# M4KL register map
File version: 0.1
Registers are 32-bit, read-write, reset 0x0 unless marked. A register's access mark holds for its fields unless they carry their own. Offsets are from the block's base; [hi:lo] are bit positions; {n}, {i} and the like mark numbered series.

## VE — Advanced Vector Engine Plus (A-VE+)
Base 0x400EB000
0x00 EN — VE enable_disable
  [0] VEEN
0x04 CPURUNTRG wo — CPU start trigger selection
  [0] VCPURT
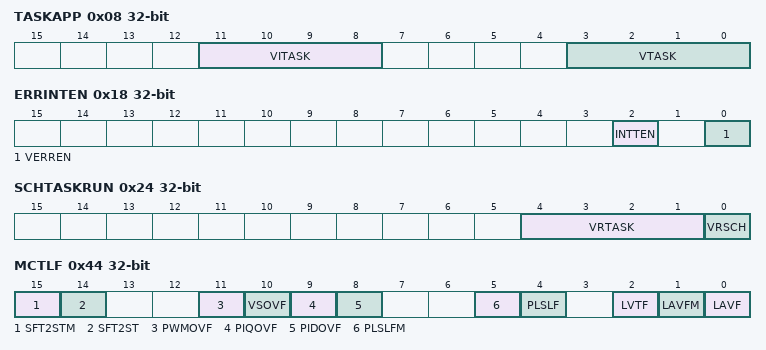
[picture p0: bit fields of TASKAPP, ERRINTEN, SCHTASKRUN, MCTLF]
0x08 TASKAPP — Task selection
  [11:8] VITASK, [3:0] VTASK
0x0C ACTSCH — Operation schedule selection
  [3:0] VACT
0x10 REPTIME — Schedule repeat count
  [3:0] VREP
0x14 TRGMODE — Start trigger mode
  [1:0] VTRG
0x18 ERRINTEN — Error interrupt enable_disable
  [2] INTTEN, [0] VERREN
0x1C COMPEND wo — VE forced termination
  [0] VCEND
0x20 ERRDET ro — Error detection
  [0] VERRD
0x24 SCHTASKRUN ro — Schedule executing flag_executing task
  [4:1] VRTASK, [0] VRSCH
{0x2C+4i} TMPREG{i} (i=0..5) — Temporary register
0x44 MCTLF — Status flags
  [15] SFT2STM, [14] SFT2ST, [11] PWMOVF, [10] VSOVF, [9] PIQOVF, [8] PIDOVF, [5] PLSLFM, [4] PLSLF, [2] LVTF, [1] LAVFM, [0] LAVF
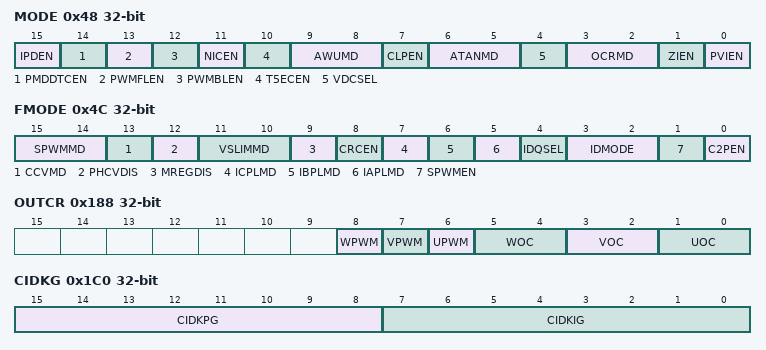
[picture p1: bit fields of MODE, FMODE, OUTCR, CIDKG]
0x48 MODE — Task control mode
  [15] IPDEN, [14] PMDDTCEN, [13] PWMFLEN, [12] PWMBLEN, [11] NICEN, [10] T5ECEN, [9:8] AWUMD, [7] CLPEN, [6:5] ATANMD, [4] VDCSEL, [3:2] OCRMD, [1] ZIEN, [0] PVIEN
0x4C FMODE — Flow control
  [15:14] SPWMMD, [13] CCVMD, [12] PHCVDIS, [11:10] VSLIMMD, [9] MREGDIS, [8] CRCEN, [7] ICPLMD, [6] IBPLMD, [5] IAPLMD, [4] IDQSEL, [3:2] IDMODE, [1] SPWMEN, [0] C2PEN
0x50 TPWM — PWM period rate (PWM period _s_ * maximum speed * 2^16) setting
  [15:0] TPWM
0x54 OMEGA — Rotation speed (speed _Hz_ _ maximum speed * 2^15) setting
  [15:0] OMEGA
0x58 THETA — Motor phase (motor phase _deg_ _ 360 * 2^16) setting
  [15:0] THETA
0x5C IDREF — d-axis reference value (current _A_ _ maximum current * 2^15)
  [15:0] IDREF
0x60 IQREF — q-axis reference value (current _A_ _ maximum current * 2^15)
  [15:0] IQREF
0x64 VD — d-axis voltage (voltage _V_ _ maximum voltage * 2^31)
0x68 VQ — q-axis voltage (voltage _V_ _ maximum voltage * 2^31)
0x6C CIDKI — Integral coefficient for PI control of d-axis
  [15:0] CIDKI
0x70 CIDKP — Proportional coefficient for PI control of d-axis
  [15:0] CIDKP
0x74 CIQKI — Integral coefficient for PI control of q-axis
  [15:0] CIQKI
0x78 CIQKP — Proportional coefficient for PI control of q-axis
  [15:0] CIQKP
0x7C VDIH — Upper 32 bits of integral term (VDI ) of d-axis voltage
0x80 VDILH — Lower 32 bits of integral term (VDI) of d-axis voltage
  [31:16] VDILH
0x84 VQIH — Upper 32 bits of integral term (VQI) of q-axis voltage
0x88 VQILH — Lower 32 bits of integral term (VQI) of q-axis voltage
  [31:16] VQILH
0x8C FPWMCHG — Switching speed (for 2-phase modulation and shift PWM)
  [15:0] FPWMCHG
0x90 PWMOFS — SHIFT2 PWM Offset register
  [15:0] PWMOFS
0x94 MINPLS — Minimum pulse width
  [15:0] MINPLS
0x98 TRGCRC — Synchronizing trigger correction value
  [15:0] TRGCRC
0x9C VDCL — Cosine value at THETA for output conversion (Q15 data)
  [15:0] VDCL
0xA0 COS — Cosine value at THETA for output conversion (Q15 data)
  [15:0] COS
0xA4 SIN — Sine value at THETA for output conversion (Q15 data)
  [15:0] SIN
0xA8 COSM — Previous cosine value for input processing (Q15 data)
  [15:0] COSM
0xAC SINM — Previous sine value for input processing (Q15 data)
  [15:0] SINM
0xB0 SECTOR — Sector information (0-11)
  [3:0] SECTOR
0xB4 SECTORM — Previous sector information for input processing (0-11)
  [3:0] SECTORM
0xB8 IAO — AD conversion result of a-phase zero-current
  [15:0] IAO
0xBC IBO — AD conversion result of b-phase zero-current
  [15:0] IBO
0xC0 ICO — AD conversion result of c-phase zero-current
  [15:0] ICO
0xC4 IAADC — AD conversion result of a-phase current
  [15:0] IAADC
0xC8 IBADC — AD conversion result of b-phase current
  [15:0] IBADC
0xCC ICADC — AD conversion result of c-phase current
  [15:0] ICADC
0xD0 VDC — DC supply voltage (voltage _V_ _ maximum voltage * 2^15)
  [15:0] VDC
0xD4 ID — d-axis current (current _A_ _ maximum current * 2^31)
0xD8 IQ — q-axis current (current _A_ _ maximum current * 2^31)
0x178 TADC — ADC start wait setting
  [15:0] TADC
0x17C CMPU — PMD control_ CMPU setting
  [15:0] VCMPU
0x180 CMPV — PMD control_ CMPV setting
  [15:0] VCMPV
0x184 CMPW — PMD control_ CMPW setting
  [15:0] VCMPW
0x188 OUTCR — PMD control_ Output control (MDOUT)
  [8] WPWM, [7] VPWM, [6] UPWM, [5:4] WOC, [3:2] VOC, [1:0] UOC
0x18C TRGCMP0 — PMD control_ TRGCMP0 setting
  [15:0] VTRGCMP0
0x190 TRGCMP1 — PMD control_ TRGCMP1 setting
  [15:0] VTRGCMP1
0x194 TRGSEL — PMD control_ Trigger selection
  [2:0] VTRGSEL
0x198 EMGRS wo — PMD control_ EMG return (EMGCR_EMGRS_)
  [0] EMGRS
0x1BC PIOLIM — PI controled output limit value setting
  [15:0] PIOLIM
0x1C0 CIDKG — PI controled d-axis coefficient range setting
  [15:8] CIDKPG, [7:0] CIDKIG
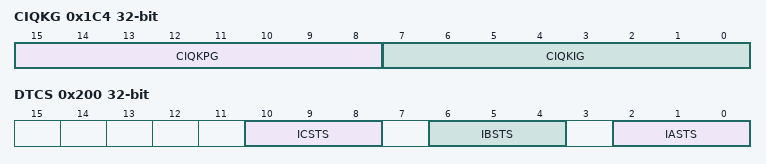
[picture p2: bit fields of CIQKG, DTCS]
0x1C4 CIQKG — PI controled q-axis coefficient range setting
  [15:8] CIQKPG, [7:0] CIQKIG
0x1C8 VSLIM — Voltage scalar limits
  [15:0] VSLIM
0x1CC VDQ — Voltage scalar
  [15:0] VDQ
0x1D0 DELTA — Declination angle
  [15:0] DELTA
0x1D4 CPHI — Motor interlinkage magnetic flux
  [15:0] CPHI
0x1D8 CLD — Motor q-axis inductance
  [15:0] CLD
0x1DC CLQ — Motor d-axis inductance
  [15:0] CLQ
0x1E0 CR — Motor resistance value
  [15:0] CR
0x1E4 CPHIG — Motor magnetic flux range setting
  [2:0] CPHIG
0x1E8 CLG — Motor inductance range setting
  [2:0] CLG
0x1EC CRG — Motor resistance range setting
  [2:0] CRG
0x1F0 VDE — Non-interference controled d-axis voltage
  [15:0] VDE
0x1F4 VQE — Non-interference controled q-axis voltage
  [15:0] VQE
0x1F8 DTC — Dead time compensation
  [15:0] DTC
0x1FC HYS — Hysteresis width for current discrimination
  [15:0] HYS
0x200 DTCS — Dead time compensation control _ status
  [10:8] ICSTS, [6:4] IBSTS, [2:0] IASTS
0x204 PWMMAX — PWM upper limit setting
  [15:0] PWMMAX
0x208 PWMMIN — PWM lower limit setting
  [15:0] PWMMIN
0x20C THTCLP — Clipped phase value setting
  [15:0] THTCLP
0x210 HYS2 — The second threshold value for determining the current polarity
  [15:0] HYS2
0x214 VALPHA — ALPHA-phase voltage
0x218 VBETA — BETA-phase voltage
0x21C VDUTYA — A-phase duty
0x220 VDUTYB — B-phase duty
0x224 VDUTYC — C-phase duty
0x228 IALPHA — ALPHA-phase current
0x22C IBETA — BETA-phase current
0x230 IA — A-phase current
0x234 IB — B-phase current
0x238 IC — C-phase current
0x23C VDELTA — VDQ Declination angle
  [15:0] VDELTA
0x240 VDCRC — d-axis voltage correction value
  [15:0] VDCRC
0x244 VQCRC — q-axis voltage correction value
  [15:0] VQCRC
